# MAX32550 register map
Vendor: Maxim Integrated; File version: 1.0
Registers are 32-bit, read-write, reset 0x0 unless marked. A register's access mark holds for its fields unless they carry their own. Offsets are from the block's base; [hi:lo] are bit positions; 'fields as' and 'values as' point back to an identical list.

## SmartCard — LCD Clock Register
Base 0x4002C000; register names take the prefix SC_
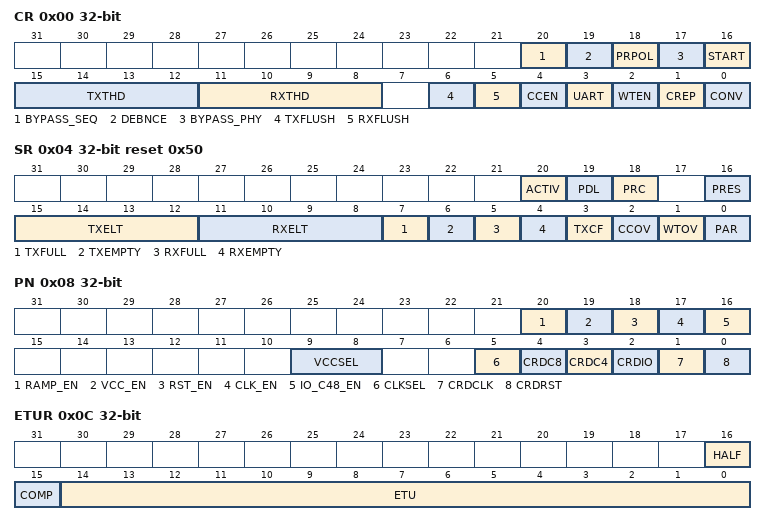
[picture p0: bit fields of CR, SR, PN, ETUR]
0x00 CR — Control Register
  [20] BYPASS_SEQ — Sequencer bypass. Disable sequencer for activation and deactivation.
    0=disable; 1=enable
  [19] DEBNCE — Enable Debounce on card insertion. When set to logic 1, this will enable the hardware debounce of the card detect pin. The debounce function shall wait for fixed timer period of stable card detect assertion before setting the SC_ISR.PRIS bit. De-assertion of SC_ISR.PRIS is immediate upon de-assertion of card detect pin.
    0=disable; 1=enable
  [18] PRPOL — Presence detect polarity. When PRPOL = 0, card presence pin shall interpret a logic 1 as card presence. When PRPOL = 1, card presence pin shall interpret a logic 0 as card presence.
    0=activeHi (Logic 1 presence detect); 1=activeLo (Logic 0 presence detect)
  [17] BYPASS_PHY — Bypass mode for smart card PHY.
    0=disable; 1=enable
  [16] START — Start bit. This bit controls software activation/deactivation of the card interface. When this bit is set, the activation sequence for the selected card is performed. When this bit is cleared, the deactivation sequence for the selected card is performed. Hardware should automatically reset the START bit during emergency deactivation.
    0=Deactivation performed; 1=Activation performed
  [15:12] TXTHD — Transmit FIFO depth. Valid range 1 to 7.
  [11:8] RXTHD — Receive FIFO depth. Valid range 1 to 7.
  [6] TXFLUSH — Transmit FIFO Flush Bit. This bit is cleared automatically by hardware.
    0=complete (No operation/complete); 1=Start operation
  [5] RXFLUSH — Receive FIFO Flush Bit. This bit is cleared automatically by hardware.
    0=complete (No operation/complete); 1=Start operation
  [4] CCEN — Clock Counter Enable Bit.
    0=disable; 1=enable
  [3] UART — Smart Card Mode Bit. Selects manual control or smart card UART control of smart card pins.
    0=manual; 1=auto
  [2] WTEN — Waiting Time Counter Enable Bit.
    0=disable; 1=enable
  [1] CREP — Character Repeat Enable Bit. Enables character retransmit on parity error.
    0=disable; 1=enable
  [0] CONV — Convention Select Bit
    0=direct; 1=indirect
0x04 SR ro reset 0x50 — Status Register
  [20] ACTIV rw — Activation Sequencer Status Flag.
    0=busy (Result not ready); 1=ready (Operation complete and result ready)
  [19] PDL — Presence detect Level Status Flag. This bit is set to a 1 when a level change has been detected on the SC_DETECT pin. If the interrupt is enabled for this flag, a system interrupt will be fired. If the interrupt enable is not set, the flag will be set, but no interrupt will fire. This bit cleared by software.
    on read: 0=noEvent (The event has not occurred); 1=occurred (The event has occurred)
  [18] PRC — Protection Card Interface Status Flag. This bit is set to a 1 by hardware when a fault is detected on the card reader interface. A fault is defined as a detection of a short-circuit condition on the RST or Vcc pin. This bit may be cleared by software to a 0.
    values as PDL
  [16] PRES — Card Presence Indication. The presence indication depends on the polarity bit (SC_CR.PRPOL): PRPOL = 0=> PRES=1 on rising edge of SC_DETECT, PRPOL = 1=>PRES=1 on falling edge of SC_DETECT pin. Cleared by hardware.
    values as PDL
  [15:12] TXELT — Number of bytes in Transmit FIFO.
  [11:8] RXELT — Number of bytes in Receive FIFO.
  [7] TXFULL — Receive FIFO Full Flag
    0=notFull; 1=full
  [6] TXEMPTY — Transmit FIFO Empty Flag
    0=notEmpty; 1=empty
  [5] RXFULL — Receive FIFO Full Flag
    0=notFull; 1=full
  [4] RXEMPTY — Receive FIFO Empty Flag
    0=notEmpty; 1=empty
  [3] TXCF — Transmit Complete Flag. Set to 1 by hardware when character has been transmitted. Cleared by software.
    values as PDL
  [2] CCOV — Clock Counter Overflow Flag. Set to 1 by hardware when clock counter has reached its maximum value.
    values as PDL
  [1] WTOV — Waiting Time Counter Overflow Flag. Set to 1 by hardware when waiting time counter overflows.
    values as PDL
  [0] PAR — Parity Error Detected Flag. Set to 1 by hardware if parity error is detected. Cleared by software.
    values as PDL
0x08 PN — Pin Register
  [20] RAMP_EN — Smart Card LDO ramp enable control, manual mode only(if SC_CR.BYPASS_SEQ=1).
    0=disable; 1=enable
  [19] VCC_EN — Smart Card supply enable control, manual mode only (if SC_CR.BYPASS_SEQ= 1).
    0=disable; 1=enable
  [18] RST_EN — Smart Card RST enable control, manual mode only (if SC_CR.BYPASS_SEQ= 1).
    0=disable; 1=enable
  [17] CLK_EN — Smart Card CLK enable control, manual mode only (if SC_CR.BYPASS_SEQ= 1).
    0=disable; 1=enable
  [16] IO_C48_EN — Smart Card IOs enable control, manual mode only (if SC_CR.BYPASS_SEQ= 1).
    0=disable; 1=enable
  [9:8] VCCSEL — Selects supply for smart card. This value must be set to select a target Vcc during card activation.
    0=v18 (1.8 V); 1=v30 (3.0 V); other=v50 (5.0 V)
  [5] CLKSEL — Smart Card Clock Control Select
    0=manual; 1=auto
  [4] CRDC8 — Smart Card C8 Pin Control. Writes to this bit set the associated pin logic level. Reads from this bit return the logic value present on the associated pin.
    0=lo (Logic 0 (low)); 1=hi (Logic 1 (high))
  [3] CRDC4 — Smart Card C4 Pin Control. Writes to this bit set the associated pin logic level. Reads from this bit return the logic value present on the associated pin.
    0=lo (Logic 0 (low)); 1=hi (Logic 1 (high))
  [2] CRDIO — Smart Card I/O Pin Control. Writes to this bit set the associated pin logic level. Reads from this bit return the logic value present on the associated pin.
    0=lo (Logic 0 (low)); 1=hi (Logic 1 (high))
  [1] CRDCLK — Smart Card Clock Pin Control. Writes to this bit set the associated pin logic level. Reads from this bit return the logic value present on the associated pin.
    0=lo (Logic 0 (low)); 1=hi (Logic 1 (high))
  [0] CRDRST — Smart Card Reset Pin Control. Writes to this bit set the associated pin logic level. Reads from this bit return the logic value present on the associated pin.
    0=lo (Logic 0 (low)); 1=hi (Logic 1 (high))
0x0C ETUR — ETU Register
  [16] HALF — Half ETU Count Selection Bit. NOTE: Guard Time (GT) and Wait Time (WT) must be doubled if HALF=1.
    0=disable; 1=enable
  [15] COMP — Compensation Mode Enable Bit. Controls 1 clock cycle subtraction of ETU value on odd bits.
    0=disable; 1=enable
  [14:0] ETU — Elemental Time Unit value. If HALF=0, Number of clocks in one asynchronous bit time. If HALF=1, Number of clocks in one half of one asynchronous bit time.
0x10 GTR 16-bit — Guard Time. Minimum time between two consecutive start bits in transmit mode. Guard Time is expressed in ETUs. Guard Time must be doubled if ETUR.HALF=1. Writes to this register may be delayed up to two ETU cycles.
0x14 WT0R — Wait Time. Least Significant 32 bits of the Wait Time Counter expressed in ETU. Wait Time must be doubled if ETUR.HALF=1. writes to this register may be delayed up to two ETU cycles.
0x18 WT1R 8-bit — Wait Time. Most Significant 8 bits of the Wait Time Counter expressed in ETU. Wait Time must be doubled if ETUR.HALF=1. Writes to this register may be delayed up to two ETU cycles.
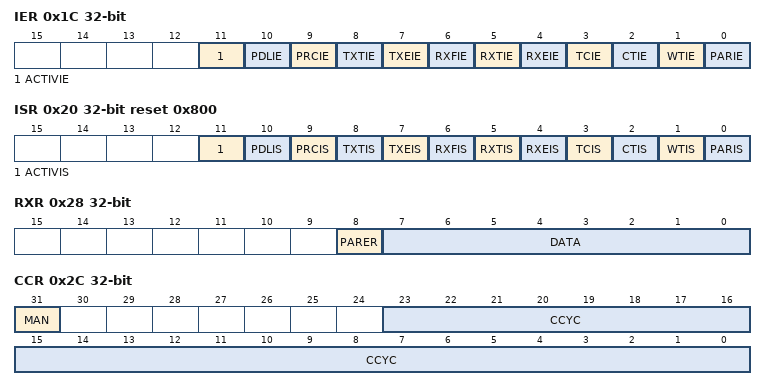
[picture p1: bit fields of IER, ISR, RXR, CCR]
0x1C IER — Interrupt Enable Register
  [11] ACTIVIE — Activation Sequencer Interrupt Enable
  [10] PDLIE — Presence Detect Interrupt Enable
  [9] PRCIE — Protection Card Interface Interrupt Enable
  [8] TXTIE — Transmit FIFO Threshold Reached Interrupt Enable
  [7] TXEIE — Transmit FIFO Empty Interrupt Enable
  [6] RXFIE — Receive FIFO Full Interrupt Enable
  [5] RXTIE — Receive FIFO Threshold Reached Interrupt Enable
  [4] RXEIE — Receive FIFO Empty Interrupt Enable
  [3] TCIE — Character Transmission Completion Interrupt Enable
  [2] CTIE — Clock Counter Overflow Interrupt Enable
  [1] WTIE — Waiting Time Overflow Interrupt Enable
  [0] PARIE — Parity Error Interrupt Enable
0x20 ISR reset 0x800 — Interrupt Status Register
  [all] fields
    0=inactive (No interrupt is pending.); 1=pending (An interrupt is pending.)
  [11] ACTIVIS — Activation Sequencer Interrupt Status Flag
  [10] PDLIS — Presence detect Interrupt Status Flag
  [9] PRCIS — Protection Card Interface Interrupt Status Flag
  [8] TXTIS — Transmit FIFO Threshold Reached Interrupt Status Flag
  [7] TXEIS — Transmit FIFO Empty Interrupt Status Flag
  [6] RXFIS — Receive FIFO Full Interrupt Status
  [5] RXTIS — Receive FIFO Threshold Reached Interrupt Status Flag
  [4] RXEIS — Receive FIFO Empty Interrupt Status Flag
  [3] TCIS — Character Transmission Completion Interrupt Status Flag
  [2] CTIS — Clock Counter Overflow Interrupt Status Flag
  [1] WTIS — Waiting Time Overflow Interrupt Status Flag
  [0] PARIS — Parity Error Interrupt Status
0x24 TXR 8-bit wo — Transmit Data. Writes to this register will load the 8 bit input data into the FIFO.
0x28 RXR ro — Receive Register
  [8] PARER — Parity Error Detect Bit. Parity error bit associated with lower bits 7:0.
    on read: 0=noError; 1=error
  [7:0] DATA — Receive Data. Reads from this register will unload 8 bit receive data from the FIFO.
0x2C CCR — Clock Counter Register
  [31] MAN — Manual Mode. The counter starts counting-down on if this bit is set instead of an AUTOMATIC hardware mechanism.
    0=disable; 1=enable
  [23:0] CCYC — Number of Clock Cycles to Count. Writes to this register may be delayed up to two ETU cycles.
